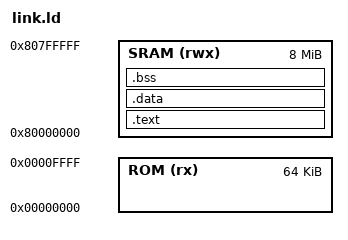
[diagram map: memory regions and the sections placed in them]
OUTPUT_ARCH("riscv")
ENTRY(_start)

MEMORY
{
    ROM (rx)  : ORIGIN = 0x00000000, LENGTH = 64K
    SRAM (rwx) : ORIGIN = 0x80000000, LENGTH = 8M
}

SECTIONS
{
    .text : {
        *(.text.start)
        *(.text*)
        *(.rodata*)
    } > SRAM
    
    .data : {
        *(.data*)
    } > SRAM
    
    .bss : {
        __bss_start = .;
        *(.bss*)
        *(COMMON)
        __bss_end = .;
    } > SRAM
    
    /DISCARD/ : {
        *(.eh_frame)
    }
}
